# A31G33x register map
Vendor: VENDOR ABOV Semiconductor Co., Ltd.; Series: A31G33x; File version: 1.0
CPU: CM0+ r0p1, little endian, no MPU, no FPU, VTOR, 2 interrupt priority bits
Registers are 32-bit, read-only, no defined reset value unless marked. A register's access mark holds for its fields unless they carry their own. Offsets are from the block's base; [hi:lo] are bit positions; {n}, {i} and the like mark numbered series.

## USB — MentorGraphics USB
Base 0x30002000
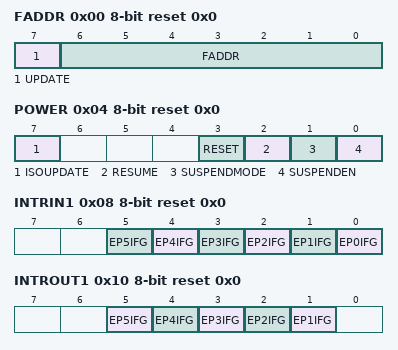
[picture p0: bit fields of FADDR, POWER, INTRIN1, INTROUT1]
0x00 FADDR 8-bit rw reset 0x0 — Function address register.
  [7] UPDATE ro — Set when FAddr is written. Cleared when the new address takes effect (at the end of the current transfer).
  [6:0] FADDR — The function address.
0x04 POWER 8-bit rw reset 0x0 — Power management register.
  [7] ISOUPDATE — When set by the CPU the MUSBFSFC will wait for an SOF token from the time InPktRdy is set before sending the packet. If an IN token is received before an SOF token, then a zero length data packet will be sent. This bit is only used by endpoints performing Isochronous transfers.
  [3] RESET ro — This read only bit is set while Reset signaling is present on the bus.
  [2] RESUME — Set by the CPU to generate Resume signaling when the function is in Suspend mode. The CPU should clear this bit after 10 ms (a maximum of 15 ms) to end Resume signaling.
  [1] SUSPENDMODE ro — Set by the USB when Suspend mode is entered. Cleared when the CPU reads the interrupt register,or sets the Resume bit of this register.
  [0] SUSPENDEN — Set by the CPU to enable entry into Suspend mode when Suspend signaling is received on the bus.
0x08 INTRIN1 8-bit reset 0x0 — Interrupt register for Endpoint 0 plus IN Endpoints 1 to 5.
  [n] EP{n}IFG (n=0..5) — IN Endpoint {n} interrupt.
0x10 INTROUT1 8-bit reset 0x0 — Interrupt register for OUT Endpoints 1 to 5.
  [n] EP{n}IFG (n=1..5) — OUT Endpoint {n} interrupt
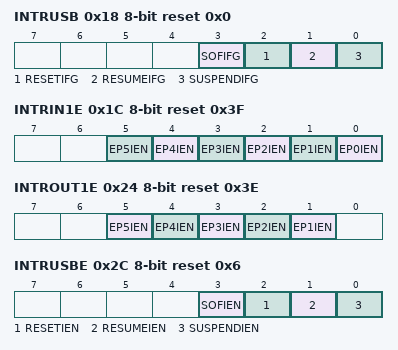
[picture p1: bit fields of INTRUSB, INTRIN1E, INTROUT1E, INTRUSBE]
0x18 INTRUSB 8-bit reset 0x0 — Interrupt register for common USB interrupts.
  [3] SOFIFG — Set at the start of each frame.
  [2] RESETIFG — Set when Reset signaling is detected on the bus.
  [1] RESUMEIFG — Set when Resume signaling is detected on the bus while the MUSBFSFC is in Suspend mode..
  [0] SUSPENDIFG — Set when Suspend signaling is detected on the bus.
0x1C INTRIN1E 8-bit rw reset 0x3F — Interrupt enable register for IntrIn1.
  [n] EP{n}IEN (n=0..5) — EP{n} Interrupt Enable
0x24 INTROUT1E 8-bit rw reset 0x3E — Interrupt enable register for IntrOut1.
  [n] EP{n}IEN (n=1..5) — Endpoint {n} Interrupt Enable
0x2C INTRUSBE 8-bit rw reset 0x6 — Interrupt enable register for IntrUSB.
  [3] SOFIEN — SOF
  [2] RESETIEN — Reset
  [1] RESUMEIEN — Resume
  [0] SUSPENDIEN — Suspend
0x30 FRAME1 8-bit reset 0x0 — Frame number bits 0 to 7.
  [7:0] FRMNO — Frame number bits 0 to 7
0x34 FRAME2 8-bit reset 0x0 — Frame number bits 8 to 10.
  [2:0] FRMNO — Frame number bits 8 to 10
0x38 INDEX 8-bit rw reset 0x0 — Index register for selecting the endpoint status and control registers.
  [3:0] INDEX — Index bits to access any endpoint control/status registers
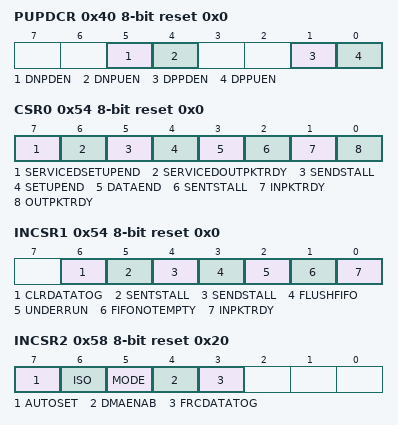
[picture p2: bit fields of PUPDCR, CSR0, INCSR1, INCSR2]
0x40 PUPDCR 8-bit rw reset 0x0 — Control register for enabling the DP/DN Pull-up and Pull down.
  [5] DNPDEN — DN Pin Pull-down resistor enable bit
  [4] DNPUEN — DN Pin Pull-up resistor enable bit
  [1] DPPDEN — DP Pin Pull-down resistor enable bit
  [0] DPPUEN — DP Pin Pull-up resistor enable bit
0x44 PHYCR 8-bit rw reset 0x1 — Control register for Enabling PHY
  [0] PHYDIS — USB PHY Master Disable bit
0x50 INMAXP 8-bit rw reset 0x0 — Maximum packet size for IN endpoint. (Index register set to select Endpoints 1 - 5 only)
  [7:0] INMAXPS — Currently-Selected IN Endpoint Maximum Packet Size except Endpoint 0
0x54 CSR0 8-bit rw reset 0x0 — Control Status register for Endpoint 0. (Index register set to select Endpoint 0)
  [7] SERVICEDSETUPEND — The CPU writes a 1 to this bit to clear the SetupEnd bit. It is cleared automatically.
  [6] SERVICEDOUTPKTRDY — The CPU writes a 1 to this bit to clear the OutPktRdy bit. It is cleared automatically
  [5] SENDSTALL — The CPU writes a 1 to this bit to terminate the current transaction. The STALL handshake will be transmitted and then this bit will be cleared automatically.
  [4] SETUPEND ro — This bit will be set when a control transaction ends before the DataEnd bit has been set. An interrupt will be generated and the FIFO flushed at this time. The bit is cleared by the CPU writing a 1 to the ServicedSetupEnd bit.
  [3] DATAEND — The CPU sets this bit: It is cleared automatically.
  [2] SENTSTALL — This bit is set when a STALL handshake is transmitted. The CPU should clear this bit.
  [1] INPKTRDY — The CPU sets this bit after loading a data packet into the FIFO. It is cleared automatically when the data packet has been transmitted. An interrupt is generated when the bit is cleared.
  [0] OUTPKTRDY ro — This bit is set when a data packet has been received. An interrupt is generated when this bit is set. The CPU clears this bit by setting the ServicedOutPktRdy bit.
0x54 INCSR1 8-bit rw reset 0x0 (alternate view of CSR0) — Control Status register 1 for IN endpoint. (Index register set to select Endpoints 1 - 5)
  [6] CLRDATATOG — The CPU writes a 1 to this bit to reset the endpoint IN data toggle to 0.
  [5] SENTSTALL — This bit is set when a STALL handshake is transmitted. The FIFO is flushed and the InPktRdy bit is cleared (see below). The CPU should clear this bit.
  [4] SENDSTALL — The CPU writes a 1 to this bit to issue a STALL handshake to an IN token. The CPU clears this bit to terminate the stall condition. This bit has no effect if the IN endpoint is in ISO mode.
  [3] FLUSHFIFO — The CPU writes a 1 to this bit to flush the next packet to be transmitted from the endpoint IN FIFO. The FIFO pointer is reset and the InPktRdy bit (below) is cleared. Note: If the FIFO contains two packets, FlushFIFO will need to be set twice to completely clear the FIFO.
  [2] UNDERRUN — In ISO mode, this bit is set when a zero length data packet is sent after receiving an IN token with the InPktRdy bit not set. In Bulk/Interrupt mode, this bit is set when a NAK is returned in response to an IN token. The CPU should clear this bit.
  [1] FIFONOTEMPTY — This bit is set when there is at least 1 packet in the IN FIFO.
  [0] INPKTRDY — The CPU sets this bit after loading a data packet into the FIFO. It is cleared automatically when a data packet has been transmitted. An interrupt is generated (if enabled) when the bit is cleared.
0x58 INCSR2 8-bit rw reset 0x20 — Control Status register 2 for IN endpoint. (Index register set to select Endpoints 1 - 5 only)
  [7] AUTOSET — If the CPU sets this bit then InPktRdy will be automatically set when data of the maximum packet size (value in InMaxP) is loaded into the IN FIFO. If a packet of less than the maximum packet size is loaded, then InPktRdy will have to be set manually.
  [6] ISO — The CPU sets this bit to enable the IN endpoint for isochronous transfers, and clears it to enable the IN endpoint for bulk or interrupt transfers.
  [5] MODE — The CPU sets this bit to enable the endpoint direction as IN, and clears it to enable the endpoint direction as OUT. Valid only where the same endpoint FIFO is used for both IN and OUT transactions.
  [4] DMAENAB — The CPU sets this bit to enable the DMA request for the IN endpoint.
  [3] FRCDATATOG — The CPU sets this bit to force the endpoint IN data toggle to switch and the data packet to be cleared from the FIFO, regardless of whether an ACK was received. This can be used by interrupt IN endpoints that are used to communicate rate feedback for isochronous endpoints.
0x5C OUTMAXP 8-bit rw reset 0x0 — Maximum packet size for OUT endpoint. (Index register set to select Endpoints 1 - 15 only)
  [7:0] OUTMAXPS — Currently-Selected OUT Endpoint Maximum Packet Size except Endpoint 0
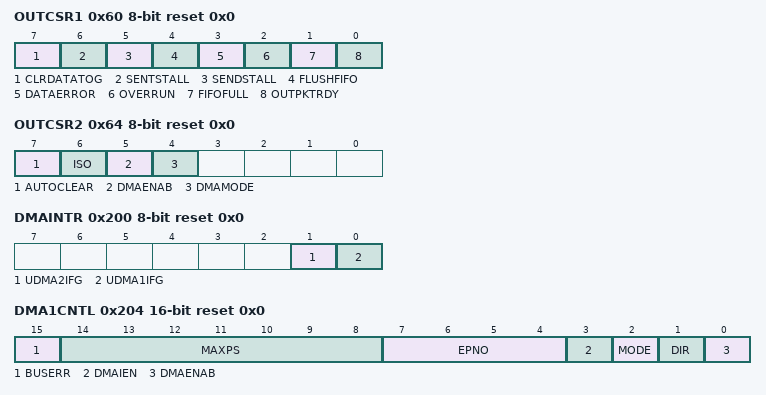
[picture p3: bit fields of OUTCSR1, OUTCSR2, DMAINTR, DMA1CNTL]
0x60 OUTCSR1 8-bit rw reset 0x0 — Control Status register 1 for OUT endpoint. (Index register set to select Endpoints 1 - 5 only)
  [7] CLRDATATOG — The CPU writes a 1 to this bit to reset the endpoint data toggle to 0.
  [6] SENTSTALL — This bit is set when a STALL handshake is transmitted. The CPU should clear this bit.
  [5] SENDSTALL — The CPU writes a 1 to this bit to issue a STALL handshake. The CPU clears this bit to terminate the stall condition. This bit has no effect if the OUT endpoint is in ISO mode.
  [4] FLUSHFIFO — The CPU writes a 1 to this bit to flush the next packet to be read from the endpoint OUT FIFO. Note: If the FIFO contains two packets, FlushFIFO will need to be set twice to completely clear the FIFO.
  [3] DATAERROR ro — This bit is set when OutPktRdy is set if the data packet has a CRC or bit-stuff error. it is cleared when OutPktRdy is cleared. The bit is only valid in ISO mode.
  [2] OVERRUN — This bit is set if an OUT packet cannot be loaded into the OUT FIFO. The CPU should clear this bit. The bit is only valid in ISO mode.
  [1] FIFOFULL ro — This bit is set when no more packets can be loaded into the OUT FIFO.
  [0] OUTPKTRDY — This bit is set when a data packet has been received. The CPU should clear this bit when the packet has been unloaded from the OUT FIFO. An interrupt is generated when the bit is set.
0x64 OUTCSR2 8-bit rw reset 0x0 — Control Status register 2 for OUT endpoint. (Index register set to select Endpoints 1 - 5 only)
  [7] AUTOCLEAR — If the CPU sets this bit then the OutPktRdy bit will be automatically cleared when a packet of OutMaxP bytes has been unloaded from the OUT FIFO. When packets of less than the maximum packet size are unloaded, OutPktRdy will have to be cleared manually.
  [6] ISO — The CPU sets this bit to enable the OUT endpoint for isochronous transfers, and clears it to enable the OUT endpoint for bulk or interrupt transfers.
  [5] DMAENAB — The CPU sets this bit to enable the DMA request for the OUT endpoint.
  [4] DMAMODE — Two modes of DMA operation are supported: DMA Mode 0 in which a DMA request is generated for all received packets, together with an interrupt (if enabled); and DMA Mode 1 in which a DMA request (but no interrupt) is generated for OUT packets of size OutMaxP bytes and an interrupt (but no DMA request) is generated for OUT packets of any other size. The CPU sets this bit to select DMA Mode 1 and clears this bit to select DMA Mode 0.
0x68 COUNT0 8-bit reset 0x0 — Number of received bytes in Endpoint 0 FIFO. (Index register set to select Endpoint 0)
  [6:0] EP0OUTCNT — number of received data bytes in the Endpoint 0 FIFO
0x68 OUTCOUNT1 8-bit reset 0x0 (alternate view of COUNT0) — Number of bytes in OUT endpoint FIFO (lower byte). (Index register set to select Endpoints 1 - 5)
  [7:0] EPOUTCNT — number of received data bytes in the Endpoint FIFO
0x6C OUTCOUNT2 8-bit reset 0x0 — Number of bytes in OUT endpoint FIFO (upper byte). (Index register set to select Endpoints 1 - 5 only)
  [2:0] EPOUTCNT — number of received data bytes in the Endpoint FIFO
{0x80+0x10*i} FIFO{i} 8-bit rw reset 0x0 (i=0..5) — Endpoint {i} FIFO Base Address
0x200 DMAINTR 8-bit reset 0x0 — Indicates pending interrupts
  [1] UDMA2IFG — USB DMA 2 Interrupt Flag bit
  [0] UDMA1IFG — USB DMA 1 Interrupt Flag bit
0x204 DMA1CNTL 16-bit rw reset 0x0 (reset mask 0x3) — DMA Channel 1 Control
  [15] BUSERR ro — BUS Error bit
  [14:8] MAXPS — DMA 1 Maximum Packet Size in units of 8 bytes
  [7:4] EPNO — DMA 1 Endpoint Number bits
  [3] DMAIEN — DMA 1 Interrupt Enable bit
  [2] MODE — DMA 1 Mode Select bit
  [1] DIR — DMA 1 Transfer Direction Select bit
  [0] DMAENAB — DMA 1 Enable bit
0x208 DMA1ADDR rw reset 0x0 (reset mask 0xFFFF) — DMA Channel 1 AHB Memory Address (32 bits)
  [31:0] ADDR — DMA Channel 1 Memory Address bits
0x20C DMA1COUNT rw reset 0x0 (reset mask 0xFFFF) — DMA Channel 1 Byte Count (32 bits)
  [31:0] TRSCNT — DMA Channel 1 Transfer Byte Count bits
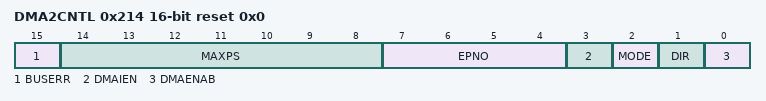
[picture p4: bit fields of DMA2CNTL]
0x214 DMA2CNTL 16-bit rw reset 0x0 (reset mask 0x3) — DMA Channel 2 Control
  [15] BUSERR ro — BUS Error bit
  [14:8] MAXPS — DMA 2 Maximum Packet Size in units of 8 bytes
  [7:4] EPNO — DMA 2 Endpoint Number bits
  [3] DMAIEN — DMA 2 Interrupt Enable bit
  [2] MODE — DMA 2 Mode Select bit
  [1] DIR — DMA 2 Transfer Direction Select bit
  [0] DMAENAB — DMA 2 Enable bit
0x218 DMA2ADDR rw reset 0x0 (reset mask 0xFFFF) — DMA Channel 2 AHB Memory Address (32 bits)
  [31:0] ADDR — DMA Channel 2 Memory Address bits
0x21C DMA2COUNT rw reset 0x0 (reset mask 0xFFFF) — DMA Channel 2 Byte Count (32 bits)
  [31:0] TRSCNT — DMA Channel 2 Transfer Byte Count bits
